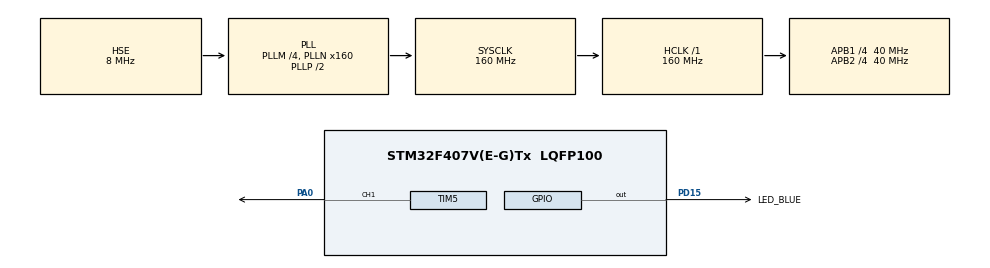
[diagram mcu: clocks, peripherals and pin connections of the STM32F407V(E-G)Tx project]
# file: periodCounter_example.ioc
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Mcu.Family=STM32F4
Mcu.Name=STM32F407V(E-G)Tx
Mcu.Package=LQFP100
NVIC.PriorityGroup=NVIC_PRIORITYGROUP_4
NVIC.TIM4_IRQn=true\:1\:0\:true\:false\:true\:true\:true
PA0-WKUP.Signal=S_TIM5_CH1
PA13.Mode=Trace_Asynchronous_SW
PA13.Signal=SYS_JTMS-SWDIO
PA14.Mode=Trace_Asynchronous_SW
PA14.Signal=SYS_JTCK-SWCLK
PB3.Mode=Trace_Asynchronous_SW
PB3.Signal=SYS_JTDO-SWO
PD15.GPIO_Label=LED_BLUE
PD15.Signal=GPIO_Output
PH0-OSC_IN.Mode=HSE-External-Oscillator
PH0-OSC_IN.Signal=RCC_OSC_IN
PH1-OSC_OUT.Mode=HSE-External-Oscillator
PH1-OSC_OUT.Signal=RCC_OSC_OUT
ProjectManager.HeapSize=0x200
ProjectManager.StackSize=0x400
ProjectManager.TargetToolchain=STM32CubeIDE
RCC.48MHZClocksFreq_Value=80000000
RCC.AHBFreq_Value=160000000
RCC.APB1CLKDivider=RCC_HCLK_DIV4
RCC.APB1Freq_Value=40000000
RCC.APB1TimFreq_Value=80000000
RCC.APB2CLKDivider=RCC_HCLK_DIV4
RCC.APB2Freq_Value=40000000
RCC.APB2TimFreq_Value=80000000
RCC.CortexFreq_Value=160000000
RCC.HCLKFreq_Value=160000000
RCC.HSE_VALUE=8000000
RCC.HSI_VALUE=16000000
RCC.LSE_VALUE=32768
RCC.PLLM=4
RCC.PLLN=160
RCC.PLLSourceVirtual=RCC_PLLSOURCE_HSE
RCC.SYSCLKFreq_VALUE=160000000
RCC.SYSCLKSource=RCC_SYSCLKSOURCE_PLLCLK
RCC.VCOOutputFreq_Value=320000000
SH.S_TIM5_CH1.0=TIM5_CH1,PWM Generation1 CH1
TIM4.Prescaler=7
TIM5.AutoReloadPreload=TIM_AUTORELOAD_PRELOAD_ENABLE
TIM5.Channel-PWM\ Generation1\ CH1=TIM_CHANNEL_1
TIM5.Period=999
TIM5.Prescaler=79
TIM5.Pulse-PWM\ Generation1\ CH1=499
VP_TIM4_VS_ClockSourceINT.Mode=Internal
VP_TIM5_VS_ClockSourceINT.Mode=Internal
board=custom

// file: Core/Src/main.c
/* USER CODE BEGIN Header */
/**
  ******************************************************************************
  * @file           : main.c
  * @brief          : Main program body
  ******************************************************************************
  * @attention
  *
  * <h2><center>&copy; Copyright (c) 2020 STMicroelectronics.
  * All rights reserved.</center></h2>
  *
  * This software component is licensed by ST under BSD 3-Clause license,
  * the "License"; You may not use this file except in compliance with the
  * License. You may obtain a copy of the License at:
  *                        opensource.org/licenses/BSD-3-Clause
  *
  ******************************************************************************
  */
/* USER CODE END Header */
#include "main.h"

/* USER CODE BEGIN Includes */
#include "fpCounter.h"
/* USER CODE END Includes */

TIM_HandleTypeDef htim4;
TIM_HandleTypeDef htim5;

/* USER CODE BEGIN PV */
double per1;
uint32_t freq1;
float duty1;
/* USER CODE END PV */

void SystemClock_Config(void);
static void MX_GPIO_Init(void);
static void MX_TIM4_Init(void);
static void MX_TIM5_Init(void);

int main(void)
{

  /* MCU Configuration--------------------------------------------------------*/

  /* Reset of all peripherals, Initializes the Flash interface and the Systick. */
  HAL_Init();

  /* Configure the system clock */
  SystemClock_Config();

  /* Initialize all configured peripherals */
  MX_GPIO_Init();
  MX_TIM4_Init();
  MX_TIM5_Init();
  /* USER CODE BEGIN 2 */

  // Init demo PWM generator timer
  fpCounter_demo();
  // Set of different frequencies for pwm generator
  uint16_t pwm_freq[] = {124, 249, 499, 999, 1999, 999, 499, 249};
  uint8_t i = 0;

	// Init counter
	fpCounter_p_init();

  /* USER CODE END 2 */

  /* Infinite loop */
  /* USER CODE BEGIN WHILE */
  while (1)
  {
  	if(i >= sizeof(pwm_freq)/sizeof(pwm_freq[0]))
  	{
  		i = 0;
  	}
  	// set new frequency by setting new ARR value (preload has to be enabled)
  	__HAL_TIM_SET_AUTORELOAD(&FPCOUNTER_DEMO_HANDLE, pwm_freq[i]);
  	// set new compare value = 1/2 of ARR to maintain 50% duty cycle
  	__HAL_TIM_SET_COMPARE(&FPCOUNTER_DEMO_HANDLE, TIM_CHANNEL_1, pwm_freq[i++]/2);
  	// Get new signal period, frequency and duty cycle
  	fpCounter_p_get(&per1, &freq1, &duty1);

  	HAL_GPIO_TogglePin(GPIOD, GPIO_PIN_15);
  	HAL_Delay(1000);
    /* USER CODE END WHILE */

  }
}

void SystemClock_Config(void)
{
  RCC_OscInitTypeDef RCC_OscInitStruct = {0};
  RCC_ClkInitTypeDef RCC_ClkInitStruct = {0};

  /** Configure the main internal regulator output voltage
  */
  __HAL_RCC_PWR_CLK_ENABLE();
  __HAL_PWR_VOLTAGESCALING_CONFIG(PWR_REGULATOR_VOLTAGE_SCALE1);
  /** Initializes the RCC Oscillators according to the specified parameters
  * in the RCC_OscInitTypeDef structure.
  */
  RCC_OscInitStruct.OscillatorType = RCC_OSCILLATORTYPE_HSE;
  RCC_OscInitStruct.HSEState = RCC_HSE_ON;
  RCC_OscInitStruct.PLL.PLLState = RCC_PLL_ON;
  RCC_OscInitStruct.PLL.PLLSource = RCC_PLLSOURCE_HSE;
  RCC_OscInitStruct.PLL.PLLM = 4;
  RCC_OscInitStruct.PLL.PLLN = 160;
  RCC_OscInitStruct.PLL.PLLP = RCC_PLLP_DIV2;
  RCC_OscInitStruct.PLL.PLLQ = 4;
  if (HAL_RCC_OscConfig(&RCC_OscInitStruct) != HAL_OK)
  {
    Error_Handler();
  }
  /** Initializes the CPU, AHB and APB buses clocks
  */
  RCC_ClkInitStruct.ClockType = RCC_CLOCKTYPE_HCLK|RCC_CLOCKTYPE_SYSCLK
                              |RCC_CLOCKTYPE_PCLK1|RCC_CLOCKTYPE_PCLK2;
  RCC_ClkInitStruct.SYSCLKSource = RCC_SYSCLKSOURCE_PLLCLK;
  RCC_ClkInitStruct.AHBCLKDivider = RCC_SYSCLK_DIV1;
  RCC_ClkInitStruct.APB1CLKDivider = RCC_HCLK_DIV4;
  RCC_ClkInitStruct.APB2CLKDivider = RCC_HCLK_DIV4;

  if (HAL_RCC_ClockConfig(&RCC_ClkInitStruct, FLASH_LATENCY_5) != HAL_OK)
  {
    Error_Handler();
  }
}

static void MX_TIM4_Init(void)
{

  TIM_ClockConfigTypeDef sClockSourceConfig = {0};
  TIM_MasterConfigTypeDef sMasterConfig = {0};

  htim4.Instance = TIM4;
  htim4.Init.Prescaler = 7;
  htim4.Init.CounterMode = TIM_COUNTERMODE_UP;
  htim4.Init.Period = 65535;
  htim4.Init.ClockDivision = TIM_CLOCKDIVISION_DIV1;
  htim4.Init.AutoReloadPreload = TIM_AUTORELOAD_PRELOAD_DISABLE;
  if (HAL_TIM_Base_Init(&htim4) != HAL_OK)
  {
    Error_Handler();
  }
  sClockSourceConfig.ClockSource = TIM_CLOCKSOURCE_INTERNAL;
  if (HAL_TIM_ConfigClockSource(&htim4, &sClockSourceConfig) != HAL_OK)
  {
    Error_Handler();
  }
  sMasterConfig.MasterOutputTrigger = TIM_TRGO_RESET;
  sMasterConfig.MasterSlaveMode = TIM_MASTERSLAVEMODE_DISABLE;
  if (HAL_TIMEx_MasterConfigSynchronization(&htim4, &sMasterConfig) != HAL_OK)
  {
    Error_Handler();
  }

}

static void MX_TIM5_Init(void)
{

  TIM_ClockConfigTypeDef sClockSourceConfig = {0};
  TIM_MasterConfigTypeDef sMasterConfig = {0};
  TIM_OC_InitTypeDef sConfigOC = {0};

  htim5.Instance = TIM5;
  htim5.Init.Prescaler = 79;
  htim5.Init.CounterMode = TIM_COUNTERMODE_UP;
  htim5.Init.Period = 999;
  htim5.Init.ClockDivision = TIM_CLOCKDIVISION_DIV1;
  htim5.Init.AutoReloadPreload = TIM_AUTORELOAD_PRELOAD_ENABLE;
  if (HAL_TIM_Base_Init(&htim5) != HAL_OK)
  {
    Error_Handler();
  }
  sClockSourceConfig.ClockSource = TIM_CLOCKSOURCE_INTERNAL;
  if (HAL_TIM_ConfigClockSource(&htim5, &sClockSourceConfig) != HAL_OK)
  {
    Error_Handler();
  }
  if (HAL_TIM_PWM_Init(&htim5) != HAL_OK)
  {
    Error_Handler();
  }
  sMasterConfig.MasterOutputTrigger = TIM_TRGO_RESET;
  sMasterConfig.MasterSlaveMode = TIM_MASTERSLAVEMODE_DISABLE;
  if (HAL_TIMEx_MasterConfigSynchronization(&htim5, &sMasterConfig) != HAL_OK)
  {
    Error_Handler();
  }
  sConfigOC.OCMode = TIM_OCMODE_PWM1;
  sConfigOC.Pulse = 499;
  sConfigOC.OCPolarity = TIM_OCPOLARITY_HIGH;
  sConfigOC.OCFastMode = TIM_OCFAST_DISABLE;
  if (HAL_TIM_PWM_ConfigChannel(&htim5, &sConfigOC, TIM_CHANNEL_1) != HAL_OK)
  {
    Error_Handler();
  }
  HAL_TIM_MspPostInit(&htim5);

}

static void MX_GPIO_Init(void)
{
  GPIO_InitTypeDef GPIO_InitStruct = {0};

  /* GPIO Ports Clock Enable */
  __HAL_RCC_GPIOH_CLK_ENABLE();
  __HAL_RCC_GPIOA_CLK_ENABLE();
  __HAL_RCC_GPIOD_CLK_ENABLE();
  __HAL_RCC_GPIOB_CLK_ENABLE();

  /*Configure GPIO pin Output Level */
  HAL_GPIO_WritePin(LED_BLUE_GPIO_Port, LED_BLUE_Pin, GPIO_PIN_RESET);

  /*Configure GPIO pin : LED_BLUE_Pin */
  GPIO_InitStruct.Pin = LED_BLUE_Pin;
  GPIO_InitStruct.Mode = GPIO_MODE_OUTPUT_PP;
  GPIO_InitStruct.Pull = GPIO_NOPULL;
  GPIO_InitStruct.Speed = GPIO_SPEED_FREQ_LOW;
  HAL_GPIO_Init(LED_BLUE_GPIO_Port, &GPIO_InitStruct);

}

void Error_Handler(void)
{
}

/************************ (C) COPYRIGHT STMicroelectronics *****END OF FILE****/
